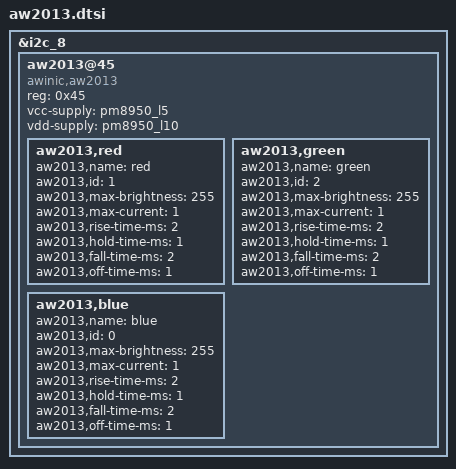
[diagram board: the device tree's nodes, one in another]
&i2c_8 { /* BLSP8 QUP1 */
	aw2013@45 {
		compatible = "awinic,aw2013";
		reg = <0x45>;
		vcc-supply = <&pm8950_l5>;
		vdd-supply = <&pm8950_l10>;
		
		aw2013,red {
			aw2013,name = "red";
			aw2013,id = <1>;
			aw2013,max-brightness = <255>;
			aw2013,max-current = <1>;
			aw2013,rise-time-ms = <2>;
			aw2013,hold-time-ms = <1>;
			aw2013,fall-time-ms = <2>;
			aw2013,off-time-ms = <1>;
		};

		aw2013,green {
			aw2013,name = "green";
			aw2013,id = <2>;
			aw2013,max-brightness = <255>;
			aw2013,max-current = <1>;
			aw2013,rise-time-ms = <2>;
			aw2013,hold-time-ms = <1>;
			aw2013,fall-time-ms = <2>;
			aw2013,off-time-ms = <1>;
		};
		aw2013,blue {
			aw2013,name = "blue";
			aw2013,id = <0>;
			aw2013,max-brightness = <255>;
			aw2013,max-current = <1>;
			aw2013,rise-time-ms = <2>;
			aw2013,hold-time-ms = <1>;
			aw2013,fall-time-ms = <2>;
			aw2013,off-time-ms = <1>;
		};
	};
};
